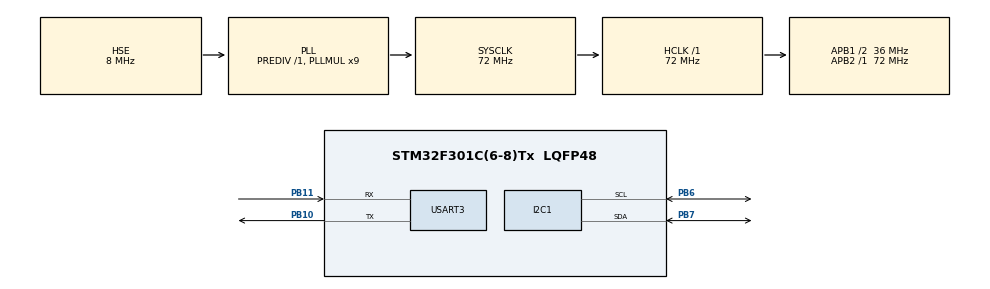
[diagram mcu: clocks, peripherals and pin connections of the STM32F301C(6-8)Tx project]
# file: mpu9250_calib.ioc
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Mcu.Family=STM32F3
Mcu.Name=STM32F301C(6-8)Tx
Mcu.Package=LQFP48
NVIC.PriorityGroup=NVIC_PRIORITYGROUP_4
PA13.Mode=Serial_Wire
PA13.Signal=SYS_JTMS-SWDIO
PA14.Mode=Serial_Wire
PA14.Signal=SYS_JTCK-SWCLK
PB10.Mode=Asynchronous
PB10.Signal=USART3_TX
PB11.Mode=Asynchronous
PB11.Signal=USART3_RX
PB6.Mode=I2C
PB6.Signal=I2C1_SCL
PB7.Mode=I2C
PB7.Signal=I2C1_SDA
PF0-OSC_IN.Mode=HSE-External-Oscillator
PF0-OSC_IN.Signal=RCC_OSC_IN
PF1-OSC_OUT.Mode=HSE-External-Oscillator
PF1-OSC_OUT.Signal=RCC_OSC_OUT
ProjectManager.HeapSize=0x200
ProjectManager.StackSize=0x400
ProjectManager.TargetToolchain=Makefile
RCC.AHBFreq_Value=72000000
RCC.APB1CLKDivider=RCC_HCLK_DIV2
RCC.APB1Freq_Value=36000000
RCC.APB1TimFreq_Value=72000000
RCC.APB2Freq_Value=72000000
RCC.APB2TimFreq_Value=72000000
RCC.CortexFreq_Value=72000000
RCC.HCLKFreq_Value=72000000
RCC.HSE_VALUE=8000000
RCC.HSI_VALUE=8000000
RCC.LSE_VALUE=32768
RCC.PLLMUL=RCC_PLL_MUL9
RCC.PLLSourceVirtual=RCC_PLLSOURCE_HSE
RCC.SYSCLKFreq_VALUE=72000000
RCC.SYSCLKSourceVirtual=RCC_SYSCLKSOURCE_PLLCLK
USART3.VirtualMode-Asynchronous=VM_ASYNC
board=custom

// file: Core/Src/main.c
/* USER CODE BEGIN Header */
/**
  ******************************************************************************
  * @file           : main.c
  * @brief          : Main program body
  ******************************************************************************
  * @attention
  *
  * Copyright (c) 2022 STMicroelectronics.
  * All rights reserved.
  *
  * This software is licensed under terms that can be found in the LICENSE file
  * in the root directory of this software component.
  * If no LICENSE file comes with this software, it is provided AS-IS.
  *
  ******************************************************************************
  */
/* USER CODE END Header */
#include "main.h"
#include "i2c.h"
#include "stm32f3xx_hal_uart.h"
#include "usart.h"
#include "gpio.h"

/* USER CODE BEGIN Includes */
#include "mpu_9250.h"
#include "stdio.h"
#include "string.h"
/* USER CODE END Includes */

void SystemClock_Config(void);
/* USER CODE BEGIN PFP */
static void USART3_print(char string[]);
/* USER CODE END PFP */

int main(void)
{
  /* USER CODE BEGIN 1 */
  dataHandleIMU himu1;
  /* USER CODE END 1 */

  /* MCU Configuration--------------------------------------------------------*/

  /* Reset of all peripherals, Initializes the Flash interface and the Systick. */
  HAL_Init();

  /* USER CODE BEGIN Init */
  char msg[100];
  char msgTest[100] = "lmao";
  /* USER CODE END Init */

  /* Configure the system clock */
  SystemClock_Config();

  /* Initialize all configured peripherals */
  MX_GPIO_Init();
  MX_I2C1_Init();
  MX_USART3_UART_Init();
  /* USER CODE BEGIN 2 */
  MPU_9250_Init();
  /* USER CODE END 2 */

  /* Infinite loop */
  /* USER CODE BEGIN WHILE */
  while (1)
  {
    IMU_measure(&himu1);
    /* USER CODE END WHILE */
    sprintf(msg, "%0.2f, %0.2f, %0.2f;%0.2f, %0.2f, %0.2f;%0.2f, %0.2f, %0.2f",
    himu1.ax, himu1.ay, himu1.az, himu1.gx, himu1.gy, himu1.gz, himu1.mx, himu1.my,
    himu1.mz);
    USART3_print(msg);
    USART3_print(msgTest);
  }
}

void SystemClock_Config(void)
{
  RCC_OscInitTypeDef RCC_OscInitStruct = {0};
  RCC_ClkInitTypeDef RCC_ClkInitStruct = {0};
  RCC_PeriphCLKInitTypeDef PeriphClkInit = {0};

  /** Initializes the RCC Oscillators according to the specified parameters
  * in the RCC_OscInitTypeDef structure.
  */
  RCC_OscInitStruct.OscillatorType = RCC_OSCILLATORTYPE_HSI|RCC_OSCILLATORTYPE_HSE;
  RCC_OscInitStruct.HSEState = RCC_HSE_ON;
  RCC_OscInitStruct.HSEPredivValue = RCC_HSE_PREDIV_DIV1;
  RCC_OscInitStruct.HSIState = RCC_HSI_ON;
  RCC_OscInitStruct.HSICalibrationValue = RCC_HSICALIBRATION_DEFAULT;
  RCC_OscInitStruct.PLL.PLLState = RCC_PLL_ON;
  RCC_OscInitStruct.PLL.PLLSource = RCC_PLLSOURCE_HSE;
  RCC_OscInitStruct.PLL.PLLMUL = RCC_PLL_MUL9;
  if (HAL_RCC_OscConfig(&RCC_OscInitStruct) != HAL_OK)
  {
    Error_Handler();
  }

  /** Initializes the CPU, AHB and APB buses clocks
  */
  RCC_ClkInitStruct.ClockType = RCC_CLOCKTYPE_HCLK|RCC_CLOCKTYPE_SYSCLK
                              |RCC_CLOCKTYPE_PCLK1|RCC_CLOCKTYPE_PCLK2;
  RCC_ClkInitStruct.SYSCLKSource = RCC_SYSCLKSOURCE_PLLCLK;
  RCC_ClkInitStruct.AHBCLKDivider = RCC_SYSCLK_DIV1;
  RCC_ClkInitStruct.APB1CLKDivider = RCC_HCLK_DIV2;
  RCC_ClkInitStruct.APB2CLKDivider = RCC_HCLK_DIV1;

  if (HAL_RCC_ClockConfig(&RCC_ClkInitStruct, FLASH_LATENCY_2) != HAL_OK)
  {
    Error_Handler();
  }
  PeriphClkInit.PeriphClockSelection = RCC_PERIPHCLK_I2C1;
  PeriphClkInit.I2c1ClockSelection = RCC_I2C1CLKSOURCE_HSI;
  if (HAL_RCCEx_PeriphCLKConfig(&PeriphClkInit) != HAL_OK)
  {
    Error_Handler();
  }
}

/* USER CODE BEGIN 4 */
static void USART3_print(char string[]){
	HAL_UART_Transmit_IT(&huart3, (uint8_t*) string, strlen(string));
}
/* USER CODE END 4 */

void Error_Handler(void)
{
  __disable_irq();
  while (1)
  {
  }
}
